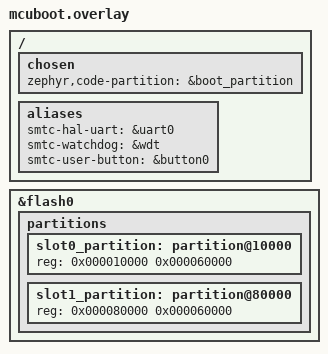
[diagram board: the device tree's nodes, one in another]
/ {
	chosen {
		zephyr,code-partition = &boot_partition;
	};
};

/ {
	aliases {
		smtc-hal-uart = &uart0;
		smtc-watchdog = &wdt;
		smtc-user-button = &button0;
	};
};

&flash0 {
	partitions {
		slot0_partition: partition@10000 {
			reg = <0x000010000 0x000060000>;
		};

		slot1_partition: partition@80000 {
			reg = <0x000080000 0x000060000>;
		};
	};
};
